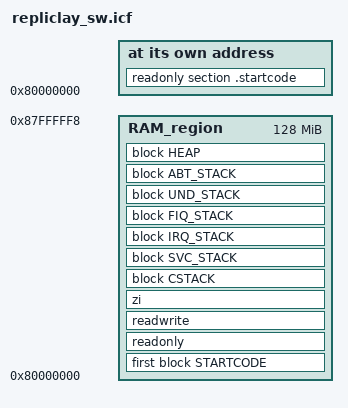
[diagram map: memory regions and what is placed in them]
/*###ICF### Section handled by ICF editor, don't touch! ****/
/*-Editor annotation file-*/
/* IcfEditorFile="$TOOLKIT_DIR$\config\ide\IcfEditor\a_v1_0.xml" */
/*-Specials-*/

/*-Memory Regions-*/
define symbol __ICFEDIT_region_ROM_start__       = 0x00000000;
define symbol __ICFEDIT_region_ROM_end__         = 0x00000000;
define symbol __ICFEDIT_region_RAM_start__       = 0x80000000;
define symbol __ICFEDIT_region_STARTCODE_start__ = __ICFEDIT_region_RAM_start__;
define symbol __ICFEDIT_region_RAM_end__         = 0x87FFFFF8;

/*-Sizes-*/
define symbol __ICFEDIT_size_STARTCODE__    = 0xFF;
define symbol __ICFEDIT_size_cstack__       = 0xA0000;
define symbol __ICFEDIT_size_svcstack__     = 0x1000;
define symbol __ICFEDIT_size_irqstack__     = 0x1000;
define symbol __ICFEDIT_size_fiqstack__     = 0x1000;
define symbol __ICFEDIT_size_undstack__     = 0x1000;
define symbol __ICFEDIT_size_abtstack__     = 0x1000;
define symbol __ICFEDIT_size_heap__         = 0xA0000;
/**** End of ICF editor section. ###ICF###*/


define memory mem with size = 4G;
define region RAM_region   = mem:[from __ICFEDIT_region_RAM_start__   to __ICFEDIT_region_RAM_end__];


define block STARTCODE with alignment = 8, size = __ICFEDIT_size_STARTCODE__    { section .startcode};
define block CSTACK    with alignment = 8, size = __ICFEDIT_size_cstack__       { };
define block SVC_STACK with alignment = 8, size = __ICFEDIT_size_svcstack__     { };
define block IRQ_STACK with alignment = 8, size = __ICFEDIT_size_irqstack__     { };
define block FIQ_STACK with alignment = 8, size = __ICFEDIT_size_fiqstack__     { };
define block UND_STACK with alignment = 8, size = __ICFEDIT_size_undstack__     { };
define block ABT_STACK with alignment = 8, size = __ICFEDIT_size_abtstack__     { };
define block HEAP      with alignment = 8, size = __ICFEDIT_size_heap__         { };

initialize by copy {  readwrite };
do not initialize  { section .noinit };

keep { section .startcode };
place at address mem: __ICFEDIT_region_STARTCODE_start__ { readonly section .startcode };

place in RAM_region   { first block STARTCODE,
                        readonly };
place in RAM_region   { readwrite };
place in RAM_region   { zi };
place in RAM_region   { block CSTACK,
                        block SVC_STACK,
                        block IRQ_STACK,
                        block FIQ_STACK,
                        block UND_STACK,
                        block ABT_STACK, 
                        block HEAP };

